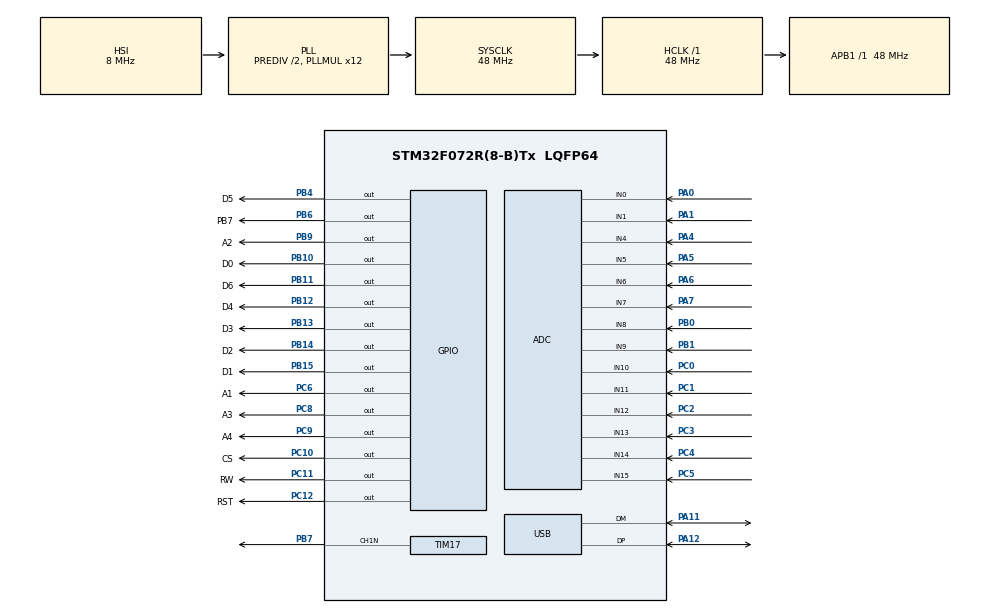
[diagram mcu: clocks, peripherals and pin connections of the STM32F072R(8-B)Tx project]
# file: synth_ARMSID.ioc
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Mcu.Family=STM32F0
Mcu.Name=STM32F072R(8-B)Tx
Mcu.Package=LQFP64
NVIC.TIM17_IRQn=true\:0\:0\:false\:false\:true\:true\:true
PA0.Mode=IN0
PA0.Signal=ADC_IN0
PA1.Mode=IN1
PA1.Signal=ADC_IN1
PA11.Mode=Device
PA11.Signal=USB_DM
PA12.Mode=Device
PA12.Signal=USB_DP
PA2.Signal=USART2_TX
PA3.Signal=USART2_RX
PA4.Mode=IN4
PA4.Signal=ADC_IN4
PA5.Mode=IN5
PA5.Signal=ADC_IN5
PA6.Mode=IN6
PA6.Signal=ADC_IN6
PA7.Mode=IN7
PA7.Signal=ADC_IN7
PB0.Mode=IN8
PB0.Signal=ADC_IN8
PB1.Mode=IN9
PB1.Signal=ADC_IN9
PB10.GPIO_Label=D0
PB10.Signal=GPIO_Output
PB11.GPIO_Label=D6
PB11.Signal=GPIO_Output
PB12.GPIO_Label=D4
PB12.Signal=GPIO_Output
PB13.GPIO_Label=D3
PB13.Signal=GPIO_Output
PB14.GPIO_Label=D2
PB14.Signal=GPIO_Output
PB15.GPIO_Label=D1
PB15.Signal=GPIO_Output
PB4.GPIO_Label=D5
PB4.Signal=GPIO_Output
PB6.GPIO_Label=PB7
PB6.Signal=GPIO_Output
PB7.Mode=PWM Generation1 CH1N
PB7.Signal=TIM17_CH1N
PB9.GPIO_Label=A2
PB9.Signal=GPIO_Output
PC0.Mode=IN10
PC0.Signal=ADC_IN10
PC1.Mode=IN11
PC1.Signal=ADC_IN11
PC10.GPIO_Label=CS
PC10.Signal=GPIO_Output
PC11.GPIO_Label=RW
PC11.Signal=GPIO_Output
PC12.GPIO_Label=RST
PC12.Signal=GPIO_Output
PC14-OSC32_IN.Mode=LSE-External-Oscillator
PC14-OSC32_IN.Signal=RCC_OSC32_IN
PC15-OSC32_OUT.Mode=LSE-External-Oscillator
PC15-OSC32_OUT.Signal=RCC_OSC32_OUT
PC2.Mode=IN12
PC2.Signal=ADC_IN12
PC3.Mode=IN13
PC3.Signal=ADC_IN13
PC4.Mode=IN14
PC4.Signal=ADC_IN14
PC5.Mode=IN15
PC5.Signal=ADC_IN15
PC6.GPIO_Label=A1
PC6.Signal=GPIO_Output
PC8.GPIO_Label=A3
PC8.Signal=GPIO_Output
PC9.GPIO_Label=A4
PC9.Signal=GPIO_Output
PF0-OSC_IN.Mode=HSE-External-Oscillator
PF0-OSC_IN.Signal=RCC_OSC_IN
PF1-OSC_OUT.Mode=HSE-External-Oscillator
PF1-OSC_OUT.Signal=RCC_OSC_OUT
ProjectManager.HeapSize=0x200
ProjectManager.StackSize=0x400
ProjectManager.TargetToolchain=STM32CubeIDE
RCC.AHBFreq_Value=48000000
RCC.APB1Freq_Value=48000000
RCC.APB1TimFreq_Value=48000000
RCC.FLatency-AdvancedSettings=FLASH_LATENCY_1
RCC.HCLKFreq_Value=48000000
RCC.PLLDivider=RCC_PREDIV_DIV2
RCC.PLLMUL=RCC_PLL_MUL12
RCC.SYSCLKFreq_VALUE=48000000
RCC.SYSCLKSource=RCC_SYSCLKSOURCE_PLLCLK
TIM17.Channel=TIM_CHANNEL_1
TIM17.Period=23
VP_TIM17_VS_ClockSourceINT.Mode=Enable_Timer
board=NUCLEO-F072RB

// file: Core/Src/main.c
/* USER CODE BEGIN Header */
/**
  ******************************************************************************
  * @file           : main.c
  * @brief          : Main program body
  ******************************************************************************
  * @attention
  *
  * <h2><center>&copy; Copyright (c) 2021 STMicroelectronics.
  * All rights reserved.</center></h2>
  *
  * This software component is licensed by ST under BSD 3-Clause license,
  * the "License"; You may not use this file except in compliance with the
  * License. You may obtain a copy of the License at:
  *                        opensource.org/licenses/BSD-3-Clause
  *
  ******************************************************************************
  */
/* USER CODE END Header */
#include "main.h"
#include "adc.h"
#include "tim.h"
#include "usb.h"
#include "gpio.h"

void SystemClock_Config(void);

int main(void)
{

  /* MCU Configuration--------------------------------------------------------*/

  /* Reset of all peripherals, Initializes the Flash interface and the Systick. */
  HAL_Init();

  /* Configure the system clock */
  SystemClock_Config();

  /* Initialize all configured peripherals */
  MX_GPIO_Init();
  MX_ADC_Init();
  MX_TIM17_Init();
  MX_USB_PCD_Init();
  /* USER CODE BEGIN 2 */
  HAL_TIM_Base_Start(htim17);
  /* USER CODE END 2 */

  /* Infinite loop */
  while (1)
  {

  }
}

void SystemClock_Config(void)
{
  RCC_OscInitTypeDef RCC_OscInitStruct = {0};
  RCC_ClkInitTypeDef RCC_ClkInitStruct = {0};
  RCC_PeriphCLKInitTypeDef PeriphClkInit = {0};

  /** Initializes the RCC Oscillators according to the specified parameters
  * in the RCC_OscInitTypeDef structure.
  */
  RCC_OscInitStruct.OscillatorType = RCC_OSCILLATORTYPE_HSI|RCC_OSCILLATORTYPE_HSI14
                              |RCC_OSCILLATORTYPE_HSI48;
  RCC_OscInitStruct.HSIState = RCC_HSI_ON;
  RCC_OscInitStruct.HSI48State = RCC_HSI48_ON;
  RCC_OscInitStruct.HSI14State = RCC_HSI14_ON;
  RCC_OscInitStruct.HSICalibrationValue = RCC_HSICALIBRATION_DEFAULT;
  RCC_OscInitStruct.HSI14CalibrationValue = 16;
  RCC_OscInitStruct.PLL.PLLState = RCC_PLL_ON;
  RCC_OscInitStruct.PLL.PLLSource = RCC_PLLSOURCE_HSI;
  RCC_OscInitStruct.PLL.PLLMUL = RCC_PLL_MUL12;
  RCC_OscInitStruct.PLL.PREDIV = RCC_PREDIV_DIV2;
  if (HAL_RCC_OscConfig(&RCC_OscInitStruct) != HAL_OK)
  {
    Error_Handler();
  }
  /** Initializes the CPU, AHB and APB buses clocks
  */
  RCC_ClkInitStruct.ClockType = RCC_CLOCKTYPE_HCLK|RCC_CLOCKTYPE_SYSCLK
                              |RCC_CLOCKTYPE_PCLK1;
  RCC_ClkInitStruct.SYSCLKSource = RCC_SYSCLKSOURCE_PLLCLK;
  RCC_ClkInitStruct.AHBCLKDivider = RCC_SYSCLK_DIV1;
  RCC_ClkInitStruct.APB1CLKDivider = RCC_HCLK_DIV1;

  if (HAL_RCC_ClockConfig(&RCC_ClkInitStruct, FLASH_LATENCY_1) != HAL_OK)
  {
    Error_Handler();
  }
  PeriphClkInit.PeriphClockSelection = RCC_PERIPHCLK_USB;
  PeriphClkInit.UsbClockSelection = RCC_USBCLKSOURCE_HSI48;

  if (HAL_RCCEx_PeriphCLKConfig(&PeriphClkInit) != HAL_OK)
  {
    Error_Handler();
  }
}

void Error_Handler(void)
{
  __disable_irq();
  while (1)
  {
  }
}

/************************ (C) COPYRIGHT STMicroelectronics *****END OF FILE****/
